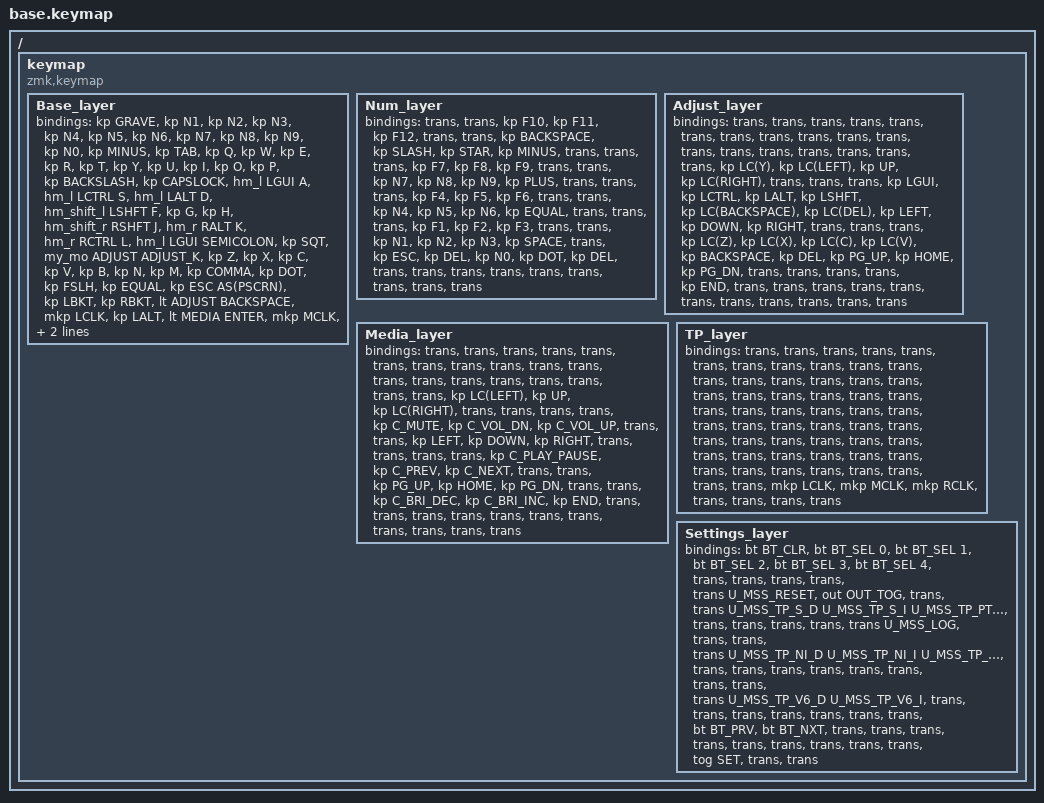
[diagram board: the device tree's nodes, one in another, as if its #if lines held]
/*
 * Copyright (c) 2020 The ZMK Contributors
 *
 * SPDX-License-Identifier: MIT
 */

// Define layer numbers
#define BASE 0
#define NUM 1
#define ADJUST 2
#define MEDIA 3
#define TP 4
#define SET 5

#define NUM_K INT1
#define ADJUST_K INT2
#define MEDIA_K INT3
#define TP_K INT4
#define SET_K INT5

#define NAV_WORD 1
#define NUM_WORD 2
#define SYM_WORD 4
#define NAV 5
#define SYM 7
#define FUNC 8
#define LOWER 10
#define MOUSE_KEYS 11


#ifdef HAS_UROB
  #define HAS_TRI_STATE
  #define HAS_NUM_WORD
#endif

// ZMK includes
#include <behaviors.dtsi>
#include <dt-bindings/zmk/keys.h>
#include <dt-bindings/zmk/bt.h>
// #include <dt-bindings/zmk/rgb.h>
#include <dt-bindings/zmk/ext_power.h>


// Personal includes
#include "includes/custom_keycodes.dtsi"
#include "includes/settings.dtsi"
#include "includes/conditional_layers.dtsi"
#include "includes/macros.dtsi"
#include "includes/combos.dtsi"
#include "includes/behaviours_homerow_mods.dtsi"
#include "includes/behaviours_mod_morph.dtsi"
#include "includes/behaviours_other.dtsi"
#include "includes/mouse_keys.dtsi"
#include "includes/mouse_tp.dtsi"
#include "includes/mouse_tp_badjeff_input_listener.dtsi"




/ {
    keymap {
        compatible = "zmk,keymap";

        Base_layer {
            bindings = <
//╭───────────────────────┬───────────────────────┬───────────────────────┬───────────────────────┬───────────────────────┬───────────────────────╮                                                       ╭───────────────────────┬───────────────────────┬───────────────────────┬───────────────────────┬───────────────────────┬───────────────────────╮
    &kp GRAVE               &kp N1                  &kp N2                  &kp N3                  &kp N4                  &kp N5                                                                          &kp N6                  &kp N7                  &kp N8                  &kp N9                  &kp N0                  &kp MINUS
//├───────────────────────┼───────────────────────┼───────────────────────┼───────────────────────┼───────────────────────┼───────────────────────┤                                                       ├───────────────────────┼───────────────────────┼───────────────────────┼───────────────────────┼───────────────────────┼───────────────────────┤
    &kp TAB                 &kp Q                   &kp W                   &kp E                   &kp R                   &kp T                                                                           &kp Y                   &kp U                   &kp I                   &kp O                   &kp P                   &kp BACKSLASH
//├───────────────────────┼───────────────────────┼───────────────────────┼───────────────────────┼───────────────────────┼───────────────────────┤                                                       ├───────────────────────┼───────────────────────┼───────────────────────┼───────────────────────┼───────────────────────┼───────────────────────┤
    &kp CAPSLOCK            &hm_l LGUI A            &hm_l LCTRL S           &hm_l LALT D            &hm_shift_l LSHFT F     &kp G                                                                           &kp H                   &hm_shift_r RSHFT J     &hm_r RALT K            &hm_r RCTRL L           &hm_l LGUI SEMICOLON    &kp SQT
//├───────────────────────┼───────────────────────┼───────────────────────┼───────────────────────┼───────────────────────┼───────────────────────┤                                                       ├───────────────────────┼───────────────────────┼───────────────────────┼───────────────────────┼───────────────────────┼───────────────────────┤
    &my_mo ADJUST ADJUST_K  &kp Z                   &kp X                   &kp C                   &kp V                   &kp B                                                                           &kp N                   &kp M                   &kp COMMA               &kp DOT                 &kp FSLH                &kp EQUAL
//╰───────────────────────┴───────────────────────┼───────────────────────┼───────────────────────┼───────────────────────┴───────────────────────╯                                                       ╰───────────────────────┴───────────────────────┼───────────────────────┼───────────────────────┼───────────────────────┴───────────────────────╯
                                                    &kp ESC                 AS(PSCRN)                                                                                                                                                                       &kp LBKT                &kp RBKT
//                                                ╰───────────────────────┴───────────────────────┼───────────────────────┬───────────────────────┬───────────────────────╮       ╭───────────────────────┬───────────────────────┬───────────────────────┼───────────────────────┴───────────────────────╯
                                                                                                    &lt ADJUST BACKSPACE    &mkp LCLK               &kp LALT                        &lt MEDIA ENTER         &mkp MCLK               &lt NUM SPACE
//                                                                                                ├───────────────────────┼───────────────────────┼───────────────────────╯       ╰───────────────────────┼───────────────────────┼───────────────────────┤
                                                                                                    &kp LSHIFT              &kp LCTRL                                                                       &hm_r RALT TAB          &mkp RCLK
//                                                                                                ╰───────────────────────┴───────────────────────╯                                                       ╰───────────────────────┴───────────────────────╯
            >;
        };

        Num_layer {
            bindings = <
//╭───────────────────────┬───────────────────────┬───────────────────────┬───────────────────────┬───────────────────────┬───────────────────────╮                                                       ╭───────────────────────┬───────────────────────┬───────────────────────┬───────────────────────┬───────────────────────┬───────────────────────╮
    &trans                  &trans                  &kp F10                 &kp F11                 &kp F12                 &trans                                                                          &trans                  &kp BACKSPACE           &kp SLASH               &kp STAR                &kp MINUS               &trans
//├───────────────────────┼───────────────────────┼───────────────────────┼───────────────────────┼───────────────────────┼───────────────────────┤                                                       ├───────────────────────┼───────────────────────┼───────────────────────┼───────────────────────┼───────────────────────┼───────────────────────┤
    &trans                  &trans                  &kp F7                  &kp F8                  &kp F9                  &trans                                                                          &trans                  &kp N7                  &kp N8                  &kp N9                  &kp PLUS                &trans
//├───────────────────────┼───────────────────────┼───────────────────────┼───────────────────────┼───────────────────────┼───────────────────────┤                                                       ├───────────────────────┼───────────────────────┼───────────────────────┼───────────────────────┼───────────────────────┼───────────────────────┤
    &trans                  &trans                  &kp F4                  &kp F5                  &kp F6                  &trans                                                                          &trans                  &kp N4                  &kp N5                  &kp N6                  &kp EQUAL               &trans
//├───────────────────────┼───────────────────────┼───────────────────────┼───────────────────────┼───────────────────────┼───────────────────────┤                                                       ├───────────────────────┼───────────────────────┼───────────────────────┼───────────────────────┼───────────────────────┼───────────────────────┤
    &trans                  &trans                  &kp F1                  &kp F2                  &kp F3                  &trans                                                                          &trans                  &kp N1                  &kp N2                  &kp N3                  &kp SPACE               &trans
//╰───────────────────────┴───────────────────────┼───────────────────────┼───────────────────────┼───────────────────────┴───────────────────────╯                                                       ╰───────────────────────┴───────────────────────┼───────────────────────┼───────────────────────┼───────────────────────┴───────────────────────╯
                                                    &kp ESC                 &kp DEL                                                                                                                                                                         &kp N0                  &kp DOT
//                                                ╰───────────────────────┴───────────────────────┼───────────────────────┬───────────────────────┬───────────────────────╮       ╭───────────────────────┬───────────────────────┬───────────────────────┼───────────────────────┴───────────────────────╯
                                                                                                    &kp DEL                 &trans                  &trans                          &trans                  &trans                  &trans                
//                                                                                                ├───────────────────────┼───────────────────────┼───────────────────────╯       ╰───────────────────────┼───────────────────────┼───────────────────────┤
                                                                                                    &trans                  &trans                                                                          &trans                  &trans                   
//                                                                                                ╰───────────────────────┴───────────────────────╯                                                       ╰───────────────────────┴───────────────────────╯
            >;
        };

        Adjust_layer {
            bindings = <
//╭───────────────────────┬───────────────────────┬───────────────────────┬───────────────────────┬───────────────────────┬───────────────────────╮                                                       ╭───────────────────────┬───────────────────────┬───────────────────────┬───────────────────────┬───────────────────────┬───────────────────────╮
    &trans                  &trans                  &trans                  &trans                  &trans                  &trans                                                                          &trans                  &trans                  &trans                  &trans                  &trans                  &trans
//├───────────────────────┼───────────────────────┼───────────────────────┼───────────────────────┼───────────────────────┼───────────────────────┤                                                       ├───────────────────────┼───────────────────────┼───────────────────────┼───────────────────────┼───────────────────────┼───────────────────────┤
    &trans                  &trans                  &trans                  &trans                  &trans                  &trans                                                                          &kp LC(Y)               &kp LC(LEFT)            &kp UP                  &kp LC(RIGHT)           &trans                  &trans
//├───────────────────────┼───────────────────────┼───────────────────────┼───────────────────────┼───────────────────────┼───────────────────────┤                                                       ├───────────────────────┼───────────────────────┼───────────────────────┼───────────────────────┼───────────────────────┼───────────────────────┤
    &trans                  &kp LGUI                &kp LCTRL               &kp LALT                &kp LSHFT               &kp LC(BACKSPACE)                                                               &kp LC(DEL)             &kp LEFT                &kp DOWN                &kp RIGHT               &trans                  &trans
//├───────────────────────┼───────────────────────┼───────────────────────┼───────────────────────┼───────────────────────┼───────────────────────┤                                                       ├───────────────────────┼───────────────────────┼───────────────────────┼───────────────────────┼───────────────────────┼───────────────────────┤
    &trans                  &kp LC(Z)               &kp LC(X)               &kp LC(C)               &kp LC(V)               &kp BACKSPACE                                                                   &kp DEL                 &kp PG_UP               &kp HOME                &kp PG_DN               &trans                  &trans
//╰───────────────────────┴───────────────────────┼───────────────────────┼───────────────────────┼───────────────────────┴───────────────────────╯                                                       ╰───────────────────────┴───────────────────────┼───────────────────────┼───────────────────────┼───────────────────────┴───────────────────────╯
                                                    &trans                  &trans                                                                                                                                                                          &kp END                 &trans
//                                                ╰───────────────────────┴───────────────────────┼───────────────────────┬───────────────────────┬───────────────────────╮       ╭───────────────────────┬───────────────────────┬───────────────────────┼───────────────────────┴───────────────────────╯
                                                                                                    &trans                  &trans                  &trans                          &trans                  &trans                  &trans                
//                                                                                                ├───────────────────────┼───────────────────────┼───────────────────────╯       ╰───────────────────────┼───────────────────────┼───────────────────────┤
                                                                                                    &trans                  &trans                                                                          &trans                  &trans                   
//                                                                                                ╰───────────────────────┴───────────────────────╯                                                       ╰───────────────────────┴───────────────────────╯
            >;
        };

        Media_layer {
            bindings = <
//╭───────────────────────┬───────────────────────┬───────────────────────┬───────────────────────┬───────────────────────┬───────────────────────╮                                                       ╭───────────────────────┬───────────────────────┬───────────────────────┬───────────────────────┬───────────────────────┬───────────────────────╮
    &trans                  &trans                  &trans                  &trans                  &trans                  &trans                                                                          &trans                  &trans                  &trans                  &trans                  &trans                  &trans
//├───────────────────────┼───────────────────────┼───────────────────────┼───────────────────────┼───────────────────────┼───────────────────────┤                                                       ├───────────────────────┼───────────────────────┼───────────────────────┼───────────────────────┼───────────────────────┼───────────────────────┤
    &trans                  &trans                  &trans                  &trans                  &trans                  &trans                                                                          &trans                  &kp LC(LEFT)            &kp UP                  &kp LC(RIGHT)           &trans                  &trans
//├───────────────────────┼───────────────────────┼───────────────────────┼───────────────────────┼───────────────────────┼───────────────────────┤                                                       ├───────────────────────┼───────────────────────┼───────────────────────┼───────────────────────┼───────────────────────┼───────────────────────┤
    &trans                  &trans                  &kp C_MUTE              &kp C_VOL_DN            &kp C_VOL_UP            &trans                                                                          &trans                  &kp LEFT                &kp DOWN                &kp RIGHT               &trans                  &trans
//├───────────────────────┼───────────────────────┼───────────────────────┼───────────────────────┼───────────────────────┼───────────────────────┤                                                       ├───────────────────────┼───────────────────────┼───────────────────────┼───────────────────────┼───────────────────────┼───────────────────────┤
    &trans                  &trans                  &kp C_PLAY_PAUSE        &kp C_PREV              &kp C_NEXT              &trans                                                                          &trans                  &kp PG_UP               &kp HOME                &kp PG_DN               &trans                  &trans
//╰───────────────────────┴───────────────────────┼───────────────────────┼───────────────────────┼───────────────────────┴───────────────────────╯                                                       ╰───────────────────────┴───────────────────────┼───────────────────────┼───────────────────────┼───────────────────────┴───────────────────────╯
                                                    &kp C_BRI_DEC           &kp C_BRI_INC                                                                                                                                                                   &kp END                 &trans
//                                                ╰───────────────────────┴───────────────────────┼───────────────────────┬───────────────────────┬───────────────────────╮       ╭───────────────────────┬───────────────────────┬───────────────────────┼───────────────────────┴───────────────────────╯
                                                                                                    &trans                  &trans                  &trans                          &trans                  &trans                  &trans                
//                                                                                                ├───────────────────────┼───────────────────────┼───────────────────────╯       ╰───────────────────────┼───────────────────────┼───────────────────────┤
                                                                                                    &trans                  &trans                                                                          &trans                  &trans                   
//                                                                                                ╰───────────────────────┴───────────────────────╯                                                       ╰───────────────────────┴───────────────────────╯
            >;
        };
        
#ifdef HAS_MOUSE_TP
        TP_layer {
            bindings = <
//╭───────────────────────┬───────────────────────┬───────────────────────┬───────────────────────┬───────────────────────┬───────────────────────╮                                                       ╭───────────────────────┬───────────────────────┬───────────────────────┬───────────────────────┬───────────────────────┬───────────────────────╮
    &trans                  &trans                  &trans                  &trans                  &trans                  &trans                                                                          &trans                  &trans                  &trans                  &trans                  &trans                  &trans
//├───────────────────────┼───────────────────────┼───────────────────────┼───────────────────────┼───────────────────────┼───────────────────────┤                                                       ├───────────────────────┼───────────────────────┼───────────────────────┼───────────────────────┼───────────────────────┼───────────────────────┤
    &trans                  &trans                  &trans                  &trans                  &trans                  &trans                                                                          &trans                  &trans                  &trans                  &trans                  &trans                  &trans
//├───────────────────────┼───────────────────────┼───────────────────────┼───────────────────────┼───────────────────────┼───────────────────────┤                                                       ├───────────────────────┼───────────────────────┼───────────────────────┼───────────────────────┼───────────────────────┼───────────────────────┤
    &trans                  &trans                  &trans                  &trans                  &trans                  &trans                                                                          &trans                  &trans                  &trans                  &trans                  &trans                  &trans
//├───────────────────────┼───────────────────────┼───────────────────────┼───────────────────────┼───────────────────────┼───────────────────────┤                                                       ├───────────────────────┼───────────────────────┼───────────────────────┼───────────────────────┼───────────────────────┼───────────────────────┤
    &trans                  &trans                  &trans                  &trans                  &trans                  &trans                                                                          &trans                  &trans                  &trans                  &trans                  &trans                  &trans
//╰───────────────────────┴───────────────────────┼───────────────────────┼───────────────────────┼───────────────────────┴───────────────────────╯                                                       ╰───────────────────────┴───────────────────────┼───────────────────────┼───────────────────────┼───────────────────────┴───────────────────────╯
                                                    &trans                  &trans                                                                                                                                                                          &trans                  &trans
//                                                ╰───────────────────────┴───────────────────────┼───────────────────────┬───────────────────────┬───────────────────────╮       ╭───────────────────────┬───────────────────────┬───────────────────────┼───────────────────────┴───────────────────────╯
                                                                                                    &trans                  &trans                  &trans                          &mkp LCLK               &mkp MCLK               &mkp RCLK 
//                                                                                                ├───────────────────────┼───────────────────────┼───────────────────────╯       ╰───────────────────────┼───────────────────────┼───────────────────────┤
                                                                                                    &trans                  &trans                                                                          &trans                  &trans             
//                                                                                                ╰───────────────────────┴───────────────────────╯                                                       ╰───────────────────────┴───────────────────────╯
            >;
        };

        Settings_layer {
            bindings = <
//╭───────────────────────┬───────────────────────┬───────────────────────┬───────────────────────┬───────────────────────┬───────────────────────╮                                                       ╭───────────────────────┬───────────────────────┬───────────────────────┬───────────────────────┬───────────────────────┬───────────────────────╮
    &bt BT_CLR              &bt BT_SEL 0            &bt BT_SEL 1            &bt BT_SEL 2            &bt BT_SEL 3            &bt BT_SEL 4                                                                    &trans                  &trans                  &trans                  &trans                  &trans                  U_MSS_RESET
//├───────────────────────┼───────────────────────┼───────────────────────┼───────────────────────┼───────────────────────┼───────────────────────┤                                                       ├───────────────────────┼───────────────────────┼───────────────────────┼───────────────────────┼───────────────────────┼───────────────────────┤
    &out OUT_TOG            &trans                  &trans                  U_MSS_TP_S_D            U_MSS_TP_S_I            U_MSS_TP_PT_I                                                                   &trans                  &trans                  &trans                  &trans                  &trans                  U_MSS_LOG
//├───────────────────────┼───────────────────────┼───────────────────────┼───────────────────────┼───────────────────────┼───────────────────────┤                                                       ├───────────────────────┼───────────────────────┼───────────────────────┼───────────────────────┼───────────────────────┼───────────────────────┤
    &trans                  &trans                  &trans                  U_MSS_TP_NI_D           U_MSS_TP_NI_I           U_MSS_TP_PT_D                                                                   &trans                  &trans                  &trans                  &trans                  &trans                  &trans
//├───────────────────────┼───────────────────────┼───────────────────────┼───────────────────────┼───────────────────────┼───────────────────────┤                                                       ├───────────────────────┼───────────────────────┼───────────────────────┼───────────────────────┼───────────────────────┼───────────────────────┤
    &trans                  &trans                  &trans                  U_MSS_TP_V6_D           U_MSS_TP_V6_I           &trans                                                                          &trans                  &trans                  &trans                  &trans                  &trans                  &trans
//╰───────────────────────┴───────────────────────┼───────────────────────┼───────────────────────┼───────────────────────┴───────────────────────╯                                                       ╰───────────────────────┴───────────────────────┼───────────────────────┼───────────────────────┼───────────────────────┴───────────────────────╯
                                                    &bt BT_PRV              &bt BT_NXT                                                                                                                                                                      &trans                  &trans
//                                                ╰───────────────────────┴───────────────────────┼───────────────────────┬───────────────────────┬───────────────────────╮       ╭───────────────────────┬───────────────────────┬───────────────────────┼───────────────────────┴───────────────────────╯
                                                                                                    &trans                  &trans                  &trans                          &trans                  &trans                  &trans 
//                                                                                                ├───────────────────────┼───────────────────────┼───────────────────────╯       ╰───────────────────────┼───────────────────────┼───────────────────────┤
                                                                                                    &trans                  &tog SET                                                                        &trans                  &trans
//                                                                                                ╰───────────────────────┴───────────────────────╯                                                       ╰───────────────────────┴───────────────────────╯
            >;
        };
#endif
    };
};

